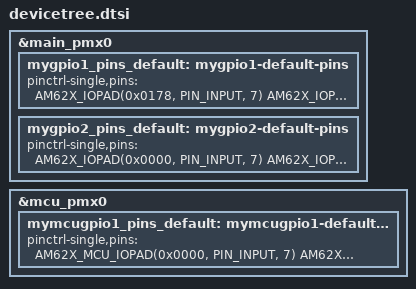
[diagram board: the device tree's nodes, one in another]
/* This file was auto-generated by TI PinMux on 6/28/2024 at 10:55:06 AM. */
/* This file should only be used as a reference. Some pins/peripherals, */
/* depending on your use case, may need additional configuration. */

&main_pmx0 {
	mygpio1_pins_default: mygpio1-default-pins {
		pinctrl-single,pins = <
			AM62X_IOPAD(0x0178, PIN_INPUT, 7) /* (V16) RGMII2_TD3.GPIO1_0 */
			AM62X_IOPAD(0x017c, PIN_INPUT, 7) /* (W19) RGMII2_RX_CTL.GPIO1_1 */
			AM62X_IOPAD(0x0180, PIN_INPUT, 7) /* (V18) RGMII2_RXC.GPIO1_2 */
			AM62X_IOPAD(0x0184, PIN_INPUT, 7) /* (W18) RGMII2_RD0.GPIO1_3 */
			AM62X_IOPAD(0x0188, PIN_INPUT, 7) /* (Y20) RGMII2_RD1.GPIO1_4 */
			AM62X_IOPAD(0x018c, PIN_INPUT, 7) /* (Y19) RGMII2_RD2.GPIO1_5 */
			AM62X_IOPAD(0x0190, PIN_INPUT, 7) /* (W20) RGMII2_RD3.GPIO1_6 */
			AM62X_IOPAD(0x0194, PIN_INPUT, 7) /* (B18) MCASP0_AXR3.GPIO1_7 */
			AM62X_IOPAD(0x0198, PIN_INPUT, 7) /* (B17) MCASP0_AXR2.GPIO1_8 */
			AM62X_IOPAD(0x019c, PIN_INPUT, 7) /* (A18) MCASP0_AXR1.GPIO1_9 */
			AM62X_IOPAD(0x01a0, PIN_INPUT, 7) /* (D18) MCASP0_AXR0.GPIO1_10 */
			AM62X_IOPAD(0x01a4, PIN_INPUT, 7) /* (C17) MCASP0_ACLKX.GPIO1_11 */
			AM62X_IOPAD(0x01a8, PIN_INPUT, 7) /* (C16) MCASP0_AFSX.GPIO1_12 */
			AM62X_IOPAD(0x01ac, PIN_INPUT, 7) /* (D15) MCASP0_AFSR.GPIO1_13 */
			AM62X_IOPAD(0x01b0, PIN_INPUT, 7) /* (D16) MCASP0_ACLKR.GPIO1_14 */
			AM62X_IOPAD(0x01b4, PIN_INPUT, 7) /* (C11) SPI0_CS0.GPIO1_15 */
			AM62X_IOPAD(0x01b8, PIN_INPUT, 7) /* (D13) SPI0_CS1.GPIO1_16 */
			AM62X_IOPAD(0x01bc, PIN_INPUT, 7) /* (D12) SPI0_CLK.GPIO1_17 */
			AM62X_IOPAD(0x01c0, PIN_INPUT, 7) /* (C12) SPI0_D0.GPIO1_18 */
			AM62X_IOPAD(0x01c4, PIN_INPUT, 7) /* (A14) SPI0_D1.GPIO1_19 */
			AM62X_IOPAD(0x01c8, PIN_INPUT, 7) /* (A13) UART0_RXD.GPIO1_20 */
			AM62X_IOPAD(0x01cc, PIN_INPUT, 7) /* (E11) UART0_TXD.GPIO1_21 */
			AM62X_IOPAD(0x01d0, PIN_INPUT, 7) /* (B14) UART0_CTSn.GPIO1_22 */
			AM62X_IOPAD(0x01d4, PIN_INPUT, 7) /* (C13) UART0_RTSn.GPIO1_23 */
			AM62X_IOPAD(0x01d8, PIN_INPUT, 7) /* (B13) MCAN0_TX.GPIO1_24 */
			AM62X_IOPAD(0x01dc, PIN_INPUT, 7) /* (A15) MCAN0_RX.GPIO1_25 */
			AM62X_IOPAD(0x01e0, PIN_INPUT, 7) /* (E12) I2C0_SCL.GPIO1_26 */
			AM62X_IOPAD(0x01e4, PIN_INPUT, 7) /* (D14) I2C0_SDA.GPIO1_27 */
			AM62X_IOPAD(0x01e8, PIN_INPUT, 7) /* (A17) I2C1_SCL.GPIO1_28 */
			AM62X_IOPAD(0x01ec, PIN_INPUT, 7) /* (A16) I2C1_SDA.GPIO1_29 */
			AM62X_IOPAD(0x01f0, PIN_INPUT, 7) /* (C14) EXT_REFCLK1.GPIO1_30 */
			AM62X_IOPAD(0x01f4, PIN_INPUT, 7) /* (B16) EXTINTn.GPIO1_31 */
			AM62X_IOPAD(0x01f8, PIN_INPUT, 7) /* (V4) MMC0_DAT7.GPIO1_32 */
			AM62X_IOPAD(0x01fc, PIN_INPUT, 7) /* (W4) MMC0_DAT6.GPIO1_33 */
			AM62X_IOPAD(0x0200, PIN_INPUT, 7) /* (W3) MMC0_DAT5.GPIO1_34 */
			AM62X_IOPAD(0x0204, PIN_INPUT, 7) /* (Y2) MMC0_DAT4.GPIO1_35 */
			AM62X_IOPAD(0x0208, PIN_INPUT, 7) /* (W1) MMC0_DAT3.GPIO1_36 */
			AM62X_IOPAD(0x020c, PIN_INPUT, 7) /* (W2) MMC0_DAT2.GPIO1_37 */
			AM62X_IOPAD(0x0210, PIN_INPUT, 7) /* (V1) MMC0_DAT1.GPIO1_38 */
			AM62X_IOPAD(0x0214, PIN_INPUT, 7) /* (V2) MMC0_DAT0.GPIO1_39 */
			AM62X_IOPAD(0x0218, PIN_INPUT, 7) /* (Y1) MMC0_CLK.GPIO1_40 */
			AM62X_IOPAD(0x0220, PIN_INPUT, 7) /* (V3) MMC0_CMD.GPIO1_41 */
			AM62X_IOPAD(0x0224, PIN_INPUT, 7) /* (C19) MMC1_DAT3.GPIO1_42 */
			AM62X_IOPAD(0x0228, PIN_INPUT, 7) /* (B20) MMC1_DAT2.GPIO1_43 */
			AM62X_IOPAD(0x022c, PIN_INPUT, 7) /* (B19) MMC1_DAT1.GPIO1_44 */
			AM62X_IOPAD(0x0230, PIN_INPUT, 7) /* (A19) MMC1_DAT0.GPIO1_45 */
			AM62X_IOPAD(0x0234, PIN_INPUT, 7) /* (A20) MMC1_CLK.GPIO1_46 */
			AM62X_IOPAD(0x023c, PIN_INPUT, 7) /* (C18) MMC1_CMD.GPIO1_47 */
			AM62X_IOPAD(0x0240, PIN_INPUT, 7) /* (C15) MMC1_SDCD.GPIO1_48 */
			AM62X_IOPAD(0x0244, PIN_INPUT, 7) /* (B15) MMC1_SDWP.GPIO1_49 */
			AM62X_IOPAD(0x0254, PIN_INPUT, 7) /* (D17) USB0_DRVVBUS.GPIO1_50 */
			AM62X_IOPAD(0x0258, PIN_INPUT, 7) /* (E16) USB1_DRVVBUS.GPIO1_51 */
		>;
	};
	mygpio2_pins_default: mygpio2-default-pins {
		pinctrl-single,pins = <
			AM62X_IOPAD(0x0000, PIN_INPUT, 7) /* (G19) OSPI0_CLK.GPIO0_0 */
			AM62X_IOPAD(0x0004, PIN_INPUT, 7) /* (G18) OSPI0_LBCLKO.GPIO0_1 */
			AM62X_IOPAD(0x0008, PIN_INPUT, 7) /* (H20) OSPI0_DQS.GPIO0_2 */
			AM62X_IOPAD(0x000c, PIN_INPUT, 7) /* (F18) OSPI0_D0.GPIO0_3 */
			AM62X_IOPAD(0x0010, PIN_INPUT, 7) /* (G17) OSPI0_D1.GPIO0_4 */
			AM62X_IOPAD(0x0014, PIN_INPUT, 7) /* (F21) OSPI0_D2.GPIO0_5 */
			AM62X_IOPAD(0x0018, PIN_INPUT, 7) /* (F20) OSPI0_D3.GPIO0_6 */
			AM62X_IOPAD(0x001c, PIN_INPUT, 7) /* (G21) OSPI0_D4.GPIO0_7 */
			AM62X_IOPAD(0x0020, PIN_INPUT, 7) /* (H21) OSPI0_D5.GPIO0_8 */
			AM62X_IOPAD(0x0024, PIN_INPUT, 7) /* (G20) OSPI0_D6.GPIO0_9 */
			AM62X_IOPAD(0x0028, PIN_INPUT, 7) /* (J21) OSPI0_D7.GPIO0_10 */
			AM62X_IOPAD(0x002c, PIN_INPUT, 7) /* (F19) OSPI0_CSn0.GPIO0_11 */
			AM62X_IOPAD(0x0030, PIN_INPUT, 7) /* (F17) OSPI0_CSn1.GPIO0_12 */
			AM62X_IOPAD(0x0034, PIN_INPUT, 7) /* (E17) OSPI0_CSn2.GPIO0_13 */
			AM62X_IOPAD(0x0038, PIN_INPUT, 7) /* (E18) OSPI0_CSn3.GPIO0_14 */
			AM62X_IOPAD(0x003c, PIN_INPUT, 7) /* (K19) GPMC0_AD0.GPIO0_15 */
			AM62X_IOPAD(0x0040, PIN_INPUT, 7) /* (L19) GPMC0_AD1.GPIO0_16 */
			AM62X_IOPAD(0x0044, PIN_INPUT, 7) /* (L20) GPMC0_AD2.GPIO0_17 */
			AM62X_IOPAD(0x0048, PIN_INPUT, 7) /* (L21) GPMC0_AD3.GPIO0_18 */
			AM62X_IOPAD(0x004c, PIN_INPUT, 7) /* (M21) GPMC0_AD4.GPIO0_19 */
			AM62X_IOPAD(0x0050, PIN_INPUT, 7) /* (L17) GPMC0_AD5.GPIO0_20 */
			AM62X_IOPAD(0x0054, PIN_INPUT, 7) /* (L18) GPMC0_AD6.GPIO0_21 */
			AM62X_IOPAD(0x0058, PIN_INPUT, 7) /* (M20) GPMC0_AD7.GPIO0_22 */
			AM62X_IOPAD(0x005c, PIN_INPUT, 7) /* (N20) GPMC0_AD8.GPIO0_23 */
			AM62X_IOPAD(0x0060, PIN_INPUT, 7) /* (N21) GPMC0_AD9.GPIO0_24 */
			AM62X_IOPAD(0x0064, PIN_INPUT, 7) /* (M17) GPMC0_AD10.GPIO0_25 */
			AM62X_IOPAD(0x0068, PIN_INPUT, 7) /* (N18) GPMC0_AD11.GPIO0_26 */
			AM62X_IOPAD(0x006c, PIN_INPUT, 7) /* (N17) GPMC0_AD12.GPIO0_27 */
			AM62X_IOPAD(0x0070, PIN_INPUT, 7) /* (N19) GPMC0_AD13.GPIO0_28 */
			AM62X_IOPAD(0x0074, PIN_INPUT, 7) /* (P19) GPMC0_AD14.GPIO0_29 */
			AM62X_IOPAD(0x0078, PIN_INPUT, 7) /* (P20) GPMC0_AD15.GPIO0_30 */
			AM62X_IOPAD(0x007c, PIN_INPUT, 7) /* (M19) GPMC0_CLK.GPIO0_31 */
			AM62X_IOPAD(0x0084, PIN_INPUT, 7) /* (K20) GPMC0_ADVn_ALE.GPIO0_32 */
			AM62X_IOPAD(0x0088, PIN_INPUT, 7) /* (K21) GPMC0_OEn_REn.GPIO0_33 */
			AM62X_IOPAD(0x008c, PIN_INPUT, 7) /* (J17) GPMC0_WEn.GPIO0_34 */
			AM62X_IOPAD(0x0090, PIN_INPUT, 7) /* (K17) GPMC0_BE0n_CLE.GPIO0_35 */
			AM62X_IOPAD(0x0094, PIN_INPUT, 7) /* (K18) GPMC0_BE1n.GPIO0_36 */
			AM62X_IOPAD(0x0098, PIN_INPUT, 7) /* (P21) GPMC0_WAIT0.GPIO0_37 */
			AM62X_IOPAD(0x009c, PIN_INPUT, 7) /* (P17) GPMC0_WAIT1.GPIO0_38 */
			AM62X_IOPAD(0x00a0, PIN_INPUT, 7) /* (J20) GPMC0_WPn.GPIO0_39 */
			AM62X_IOPAD(0x00a4, PIN_INPUT, 7) /* (J19) GPMC0_DIR.GPIO0_40 */
			AM62X_IOPAD(0x00a8, PIN_INPUT, 7) /* (J18) GPMC0_CSn0.GPIO0_41 */
			AM62X_IOPAD(0x00ac, PIN_INPUT, 7) /* (H17) GPMC0_CSn1.GPIO0_42 */
			AM62X_IOPAD(0x00b0, PIN_INPUT, 7) /* (H18) GPMC0_CSn2.GPIO0_43 */
			AM62X_IOPAD(0x00b4, PIN_INPUT, 7) /* (H19) GPMC0_CSn3.GPIO0_44 */
			AM62X_IOPAD(0x00b8, PIN_INPUT, 7) /* (R21) VOUT0_DATA0.GPIO0_45 */
			AM62X_IOPAD(0x00bc, PIN_INPUT, 7) /* (P18) VOUT0_DATA1.GPIO0_46 */
			AM62X_IOPAD(0x00c0, PIN_INPUT, 7) /* (R18) VOUT0_DATA2.GPIO0_47 */
			AM62X_IOPAD(0x00c4, PIN_INPUT, 7) /* (R19) VOUT0_DATA3.GPIO0_48 */
			AM62X_IOPAD(0x00c8, PIN_INPUT, 7) /* (R20) VOUT0_DATA4.GPIO0_49 */
			AM62X_IOPAD(0x00cc, PIN_INPUT, 7) /* (T20) VOUT0_DATA5.GPIO0_50 */
			AM62X_IOPAD(0x00d0, PIN_INPUT, 7) /* (T21) VOUT0_DATA6.GPIO0_51 */
			AM62X_IOPAD(0x00d4, PIN_INPUT, 7) /* (T19) VOUT0_DATA7.GPIO0_52 */
			AM62X_IOPAD(0x00d8, PIN_INPUT, 7) /* (U21) VOUT0_DATA8.GPIO0_53 */
			AM62X_IOPAD(0x00dc, PIN_INPUT, 7) /* (R17) VOUT0_DATA9.GPIO0_54 */
			AM62X_IOPAD(0x00e0, PIN_INPUT, 7) /* (T18) VOUT0_DATA10.GPIO0_55 */
			AM62X_IOPAD(0x00e4, PIN_INPUT, 7) /* (U20) VOUT0_DATA11.GPIO0_56 */
			AM62X_IOPAD(0x00e8, PIN_INPUT, 7) /* (U19) VOUT0_DATA12.GPIO0_57 */
			AM62X_IOPAD(0x00ec, PIN_INPUT, 7) /* (V21) VOUT0_DATA13.GPIO0_58 */
			AM62X_IOPAD(0x00f0, PIN_INPUT, 7) /* (U18) VOUT0_DATA14.GPIO0_59 */
			AM62X_IOPAD(0x00f4, PIN_INPUT, 7) /* (V20) VOUT0_DATA15.GPIO0_60 */
			AM62X_IOPAD(0x00f8, PIN_INPUT, 7) /* (W21) VOUT0_HSYNC.GPIO0_61 */
			AM62X_IOPAD(0x00fc, PIN_INPUT, 7) /* (T17) VOUT0_DE.GPIO0_62 */
			AM62X_IOPAD(0x0100, PIN_INPUT, 7) /* (T16) VOUT0_VSYNC.GPIO0_63 */
			AM62X_IOPAD(0x0104, PIN_INPUT, 7) /* (U17) VOUT0_PCLK.GPIO0_64 */
			AM62X_IOPAD(0x0108, PIN_INPUT, 7) /* (E20) MMC2_DAT3.GPIO0_65 */
			AM62X_IOPAD(0x010c, PIN_INPUT, 7) /* (E19) MMC2_DAT2.GPIO0_66 */
			AM62X_IOPAD(0x0110, PIN_INPUT, 7) /* (D21) MMC2_DAT1.GPIO0_67 */
			AM62X_IOPAD(0x0114, PIN_INPUT, 7) /* (B21) MMC2_DAT0.GPIO0_68 */
			AM62X_IOPAD(0x0118, PIN_INPUT, 7) /* (E21) MMC2_CLK.GPIO0_69 */
			AM62X_IOPAD(0x0120, PIN_INPUT, 7) /* (C21) MMC2_CMD.GPIO0_70 */
			AM62X_IOPAD(0x0124, PIN_INPUT, 7) /* (D20) MMC2_SDCD.GPIO0_71 */
			AM62X_IOPAD(0x0128, PIN_INPUT, 7) /* (C20) MMC2_SDWP.GPIO0_72 */
			AM62X_IOPAD(0x012c, PIN_INPUT, 7) /* (V15) RGMII1_TX_CTL.GPIO0_73 */
			AM62X_IOPAD(0x0130, PIN_INPUT, 7) /* (W16) RGMII1_TXC.GPIO0_74 */
			AM62X_IOPAD(0x0134, PIN_INPUT, 7) /* (U14) RGMII1_TD0.GPIO0_75 */
			AM62X_IOPAD(0x0138, PIN_INPUT, 7) /* (AA19) RGMII1_TD1.GPIO0_76 */
			AM62X_IOPAD(0x013c, PIN_INPUT, 7) /* (Y17) RGMII1_TD2.GPIO0_77 */
			AM62X_IOPAD(0x0140, PIN_INPUT, 7) /* (AA18) RGMII1_TD3.GPIO0_78 */
			AM62X_IOPAD(0x0144, PIN_INPUT, 7) /* (W14) RGMII1_RX_CTL.GPIO0_79 */
			AM62X_IOPAD(0x0148, PIN_INPUT, 7) /* (AA16) RGMII1_RXC.GPIO0_80 */
			AM62X_IOPAD(0x014c, PIN_INPUT, 7) /* (W15) RGMII1_RD0.GPIO0_81 */
			AM62X_IOPAD(0x0150, PIN_INPUT, 7) /* (Y16) RGMII1_RD1.GPIO0_82 */
			AM62X_IOPAD(0x0154, PIN_INPUT, 7) /* (AA17) RGMII1_RD2.GPIO0_83 */
			AM62X_IOPAD(0x0158, PIN_INPUT, 7) /* (Y15) RGMII1_RD3.GPIO0_84 */
			AM62X_IOPAD(0x015c, PIN_INPUT, 7) /* (U16) MDIO0_MDIO.GPIO0_85 */
			AM62X_IOPAD(0x0160, PIN_INPUT, 7) /* (V17) MDIO0_MDC.GPIO0_86 */
			AM62X_IOPAD(0x0164, PIN_INPUT, 7) /* (Y21) RGMII2_TX_CTL.GPIO0_87 */
			AM62X_IOPAD(0x0168, PIN_INPUT, 7) /* (Y18) RGMII2_TXC.GPIO0_88 */
			AM62X_IOPAD(0x016c, PIN_INPUT, 7) /* (AA20) RGMII2_TD0.GPIO0_89 */
			AM62X_IOPAD(0x0170, PIN_INPUT, 7) /* (U15) RGMII2_TD1.GPIO0_90 */
			AM62X_IOPAD(0x0174, PIN_INPUT, 7) /* (W17) RGMII2_TD2.GPIO0_91 */
		>;
	};
};


&mcu_pmx0 {
	mymcugpio1_pins_default: mymcugpio1-default-pins {
		pinctrl-single,pins = <
			AM62X_MCU_IOPAD(0x0000, PIN_INPUT, 7) /* (E7) MCU_SPI0_CS0.MCU_GPIO0_0 */
			AM62X_MCU_IOPAD(0x0004, PIN_INPUT, 7) /* (C8) MCU_SPI0_CS1.MCU_GPIO0_1 */
			AM62X_MCU_IOPAD(0x0008, PIN_INPUT, 7) /* (B7) MCU_SPI0_CLK.MCU_GPIO0_2 */
			AM62X_MCU_IOPAD(0x000c, PIN_INPUT, 7) /* (E8) MCU_SPI0_D0.MCU_GPIO0_3 */
			AM62X_MCU_IOPAD(0x0010, PIN_INPUT, 7) /* (D8) MCU_SPI0_D1.MCU_GPIO0_4 */
			AM62X_MCU_IOPAD(0x0014, PIN_INPUT, 7) /* (A8) MCU_UART0_RXD.MCU_GPIO0_5 */
			AM62X_MCU_IOPAD(0x0018, PIN_INPUT, 7) /* (B6) MCU_UART0_TXD.MCU_GPIO0_6 */
			AM62X_MCU_IOPAD(0x001c, PIN_INPUT, 7) /* (B8) MCU_UART0_CTSn.MCU_GPIO0_7 */
			AM62X_MCU_IOPAD(0x0020, PIN_INPUT, 7) /* (D7) MCU_UART0_RTSn.MCU_GPIO0_8 */
			AM62X_MCU_IOPAD(0x0024, PIN_INPUT, 7) /* (B5) WKUP_UART0_RXD.MCU_GPIO0_9 */
			AM62X_MCU_IOPAD(0x0028, PIN_INPUT, 7) /* (C6) WKUP_UART0_TXD.MCU_GPIO0_10 */
			AM62X_MCU_IOPAD(0x002c, PIN_INPUT, 7) /* (A7) WKUP_UART0_CTSn.MCU_GPIO0_11 */
			AM62X_MCU_IOPAD(0x0030, PIN_INPUT, 7) /* (B4) WKUP_UART0_RTSn.MCU_GPIO0_12 */
			AM62X_MCU_IOPAD(0x0034, PIN_INPUT, 7) /* (C5) MCU_MCAN0_TX.MCU_GPIO0_13 */
			AM62X_MCU_IOPAD(0x0038, PIN_INPUT, 7) /* (C4) MCU_MCAN0_RX.MCU_GPIO0_14 */
			AM62X_MCU_IOPAD(0x003c, PIN_INPUT, 7) /* (D5) MCU_MCAN1_TX.MCU_GPIO0_15 */
			AM62X_MCU_IOPAD(0x0040, PIN_INPUT, 7) /* (D6) MCU_MCAN1_RX.MCU_GPIO0_16 */
			AM62X_MCU_IOPAD(0x0044, PIN_INPUT, 7) /* (B9) MCU_I2C0_SCL.MCU_GPIO0_17 */
			AM62X_MCU_IOPAD(0x0048, PIN_INPUT, 7) /* (A10) MCU_I2C0_SDA.MCU_GPIO0_18 */
			AM62X_MCU_IOPAD(0x004c, PIN_INPUT, 7) /* (E9) WKUP_I2C0_SCL.MCU_GPIO0_19 */
			AM62X_MCU_IOPAD(0x0050, PIN_INPUT, 7) /* (A9) WKUP_I2C0_SDA.MCU_GPIO0_20 */
			AM62X_MCU_IOPAD(0x005c, PIN_INPUT, 7) /* (A12) MCU_RESETSTATz.MCU_GPIO0_21 */
			AM62X_MCU_IOPAD(0x0080, PIN_INPUT, 7) /* (C7) PMIC_LPM_EN0.MCU_GPIO0_22 */
			AM62X_MCU_IOPAD(0x0084, PIN_INPUT, 7) /* (B12) WKUP_CLKOUT0.MCU_GPIO0_23 */
		>;
	};
};
